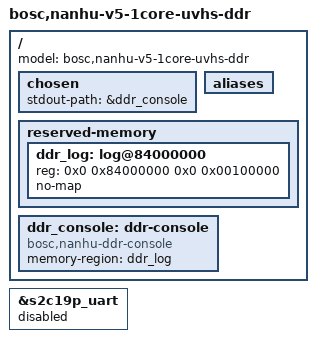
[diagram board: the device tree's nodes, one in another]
// SPDX-License-Identifier: (GPL-2.0 OR MIT)
#include "nanhu-v5-1core-uvhs.dts"

/ {
	model = "bosc,nanhu-v5-1core-uvhs-ddr";

	chosen {
		stdout-path = &ddr_console;
	};

	aliases {
		/delete-property/ serial0;
	};

	reserved-memory {
		#address-cells = <2>;
		#size-cells = <2>;
		ranges;
		ddr_log: log@84000000 {
			reg = <0x0 0x84000000 0x0 0x00100000>;
			no-map;
		};
	};

	ddr_console: ddr-console {
		compatible = "bosc,nanhu-ddr-console";
		memory-region = <&ddr_log>;
		status = "okay";
	};
};

&s2c19p_uart {
	status = "disabled";
};
